# MCU_FSS0_FSAS_0_FSAS_CFG register map
Vendor: Texas Instruments
Peripheral module from a debugger description file (folder J7_AHP).
Registers are 32-bit, access not given, reset 0x0 unless marked. A register's access mark holds for its fields unless they carry their own. Offsets are as the file gives them; lines under a group give offsets from that group; [hi:lo] are bit positions; {n}, {i} and the like mark numbered series; 'fields as' and 'values as' point back to an identical list; <NAME> marks a mode.

## MCU_FSS0_FSAS_0_FSAS_CFG
0x00 FSAS__FSAS_MMR_CFG__FSAS_GENREGS_EOI rw
  [0] EOI_VECTOR — Write with bit position of targeted interrupt. (E.g. Ext FSS ECC is bit 0). Upon write, level interrupt will clear and if un-serviced will issue another pulse interrupt
0x00 FSAS__FSAS_MMR_CFG__FSAS_GENREGS_ECC_BLOCK_ADR ro
  [31:5] ECC_ERROR_BLOCK_ADDR — ECC 32 byte aligned block address
0x00 FSAS__FSAS_MMR_CFG__FSAS_GENREGS_ECC_RGSTRT rw
  [19:0] R_START — This defines the start of the ECC region in 4KBytes steps. Address start = {start[19:0], 0x000} 0x0 means the start is 0x0000_0000 0x1 means the start is 0x0000_1000 0xA means the start is 0x0000_A000 Note the offset + size should be <= 4GBytes, wrap around is not supported.
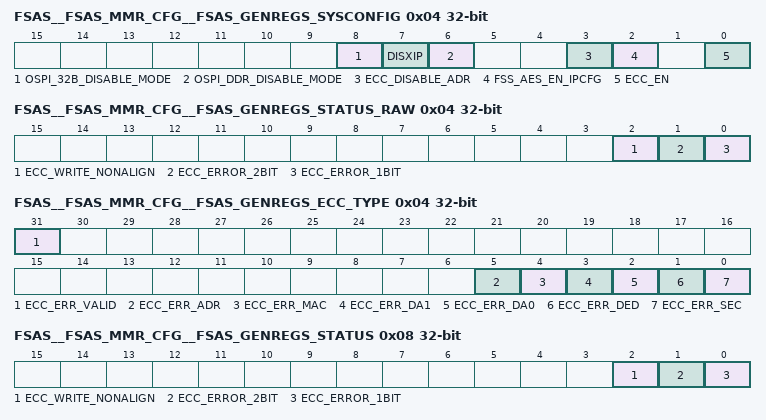
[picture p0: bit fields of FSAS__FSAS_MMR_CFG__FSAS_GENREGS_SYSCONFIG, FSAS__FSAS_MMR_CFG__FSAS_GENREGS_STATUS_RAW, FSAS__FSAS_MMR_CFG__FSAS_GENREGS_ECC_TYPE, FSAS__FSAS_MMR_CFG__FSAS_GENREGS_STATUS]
0x04 FSAS__FSAS_MMR_CFG__FSAS_GENREGS_SYSCONFIG access per field
  [8] OSPI_32B_DISABLE_MODE rw — 0 OSPI 32bit mode enabled. 1 OSPI 32bit mode disabled
  [7] DISXIP rw — 0 XIP Prefetch Enabled. 1 XIP prefetch disabled
  [6] OSPI_DDR_DISABLE_MODE rw — 0 OSPI DDR mode enabled. 1 OSPI DDR mode disabled
  [3] ECC_DISABLE_ADR rw — 0 Block address within ECC calculation, 1 Block address not within ECC calculation
  [2] FSS_AES_EN_IPCFG ro — 1 select security, 0 disable security
  [0] ECC_EN rw — 0 ECC disabled. 1 ECC enabled
0x04 FSAS__FSAS_MMR_CFG__FSAS_GENREGS_STATUS_RAW
  [2] ECC_WRITE_NONALIGN — Write is not aligned to 32B boundary or not a multiple of 32B (access R/W1TS)
  [1] ECC_ERROR_2BIT — ECC error on 2 bits. Not correctable (access R/W1TS)
  [0] ECC_ERROR_1BIT — ECC error on 1 bits. correctable (access R/W1TS)
0x04 FSAS__FSAS_MMR_CFG__FSAS_GENREGS_ECC_TYPE
  [31] ECC_ERR_VALID — When set indicates that there is valid ECC error information available, Writing a one to this register will pop the top of the stack (access R/W1TC)
  [5] ECC_ERR_ADR ro — When set indicates that there was a single error detected within the address field
  [4] ECC_ERR_MAC ro — When set indicates that there was a single error detected within the MAC field
  [3] ECC_ERR_DA1 ro — When set indicates that there was a single error detected within the High Data word
  [2] ECC_ERR_DA0 ro — When set indicates that there was a single error detected within the Low Data word
  [1] ECC_ERR_DED ro — When set indicates that there was a double error detected for the block
  [0] ECC_ERR_SEC ro — hen set indicates that there was a single error detected for the block
0x04 FSAS__FSAS_MMR_CFG__FSAS_GENREGS_ECC_RGSIZ rw
  [19:0] R_SIZE — This defines the size of the ECC region in 4KBytes steps 0x0 means the size is zero and disabled 0x1 means the size is 4KBytes 0xA means the size is 40KBytes 0xF_FFFF means the size is 4GBytes Note the offset + size should be <= 4GBytes, wrap around is not supported.
0x08 FSAS__FSAS_MMR_CFG__FSAS_GENREGS_FRAG_ADR rw
  [31:0] FRAG_ADDR — This address is used to determine the boundary of frag_hi and flag_lo
0x08 FSAS__FSAS_MMR_CFG__FSAS_GENREGS_STATUS
  [2] ECC_WRITE_NONALIGN — Write is not aligned to 32B boundary or not a multiple of 32B (access R/W1TC)
  [1] ECC_ERROR_2BIT — ECC error on 2 bits. Not correctable (access R/W1TC)
  [0] ECC_ERROR_1BIT — ECC error on 1 bits. correctable (access R/W1TC)
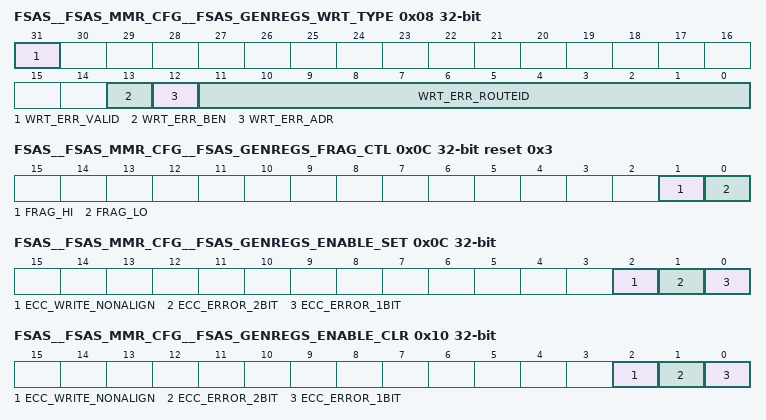
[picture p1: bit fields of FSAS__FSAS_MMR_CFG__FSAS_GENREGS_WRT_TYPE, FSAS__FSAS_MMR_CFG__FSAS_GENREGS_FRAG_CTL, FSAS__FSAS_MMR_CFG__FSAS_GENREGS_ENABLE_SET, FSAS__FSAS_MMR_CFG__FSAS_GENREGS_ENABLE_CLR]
0x08 FSAS__FSAS_MMR_CFG__FSAS_GENREGS_WRT_TYPE
  [31] WRT_ERR_VALID — When set indicates that there is valid write error information available, Writing a one to this register will pop the top of the stack (access R/W1TC)
  [13] WRT_ERR_BEN ro — When set indicates that there was a write error due to a non-contiguous byte enables
  [12] WRT_ERR_ADR ro — When set indicates that there was a write error due to a non-aligned address
  [11:0] WRT_ERR_ROUTEID ro — Indicates the Route ID for the Master that caused the write error
0x0C FSAS__FSAS_MMR_CFG__FSAS_GENREGS_FRAG_CTL rw reset 0x3
  [1] FRAG_HI — When set any address greater than or equal to frag_addr will be fragmented to 16 bits
  [0] FRAG_LO — When set any address less than frag_addr will be fragmented to 16 bits
0x0C FSAS__FSAS_MMR_CFG__FSAS_GENREGS_ENABLE_SET
  fields as FSAS__FSAS_MMR_CFG__FSAS_GENREGS_STATUS_RAW
0x10 FSAS__FSAS_MMR_CFG__FSAS_GENREGS_ENABLE_CLR
  fields as FSAS__FSAS_MMR_CFG__FSAS_GENREGS_STATUS
